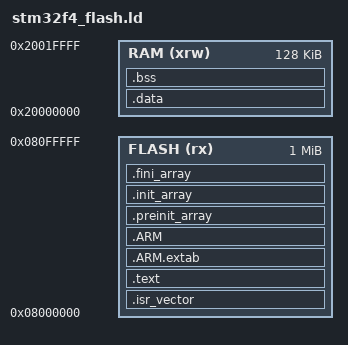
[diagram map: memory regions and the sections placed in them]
ENTRY(Reset_Handler)

/* Stack is placed in the 64KB CCM memory */
/* NB. CCM memory cannot be accessed by peripherals or DMA! */
/* Always use static/global variables with peripherals/DMA. */
_estack = 0x10000000 + 64K;

MEMORY
{
	FLASH (rx)      : ORIGIN = 0x08000000, LENGTH = 1024K
	RAM (xrw)       : ORIGIN = 0x20000000, LENGTH = 128K
}

SECTIONS
{
	/* Reset Vector */
	.isr_vector :
	{
		. = ALIGN(4);
		KEEP(*(.isr_vector))
		. = ALIGN(4);
	} >FLASH

	.text :
	{
		. = ALIGN(4);
		*(.text)
		*(.text*)
		*(.rodata)
		*(.rodata*)
		*(.glue_7)         /* glue arm to thumb code */
		*(.glue_7t)        /* glue thumb to arm code */
		*(.eh_frame)

		KEEP (*(.init))
		KEEP (*(.fini))

		. = ALIGN(4);
		_etext = .;
		_exit = .;
	} >FLASH

	.ARM.extab : { *(.ARM.extab* .gnu.linkonce.armextab.*) } >FLASH
	.ARM : {
		__exidx_start = .;
		*(.ARM.exidx*)
		__exidx_end = .;
	} >FLASH

	.preinit_array :
	{
		PROVIDE_HIDDEN (__preinit_array_start = .);
		KEEP (*(.preinit_array*))
		PROVIDE_HIDDEN (__preinit_array_end = .);
	} >FLASH

	.init_array :
	{
		PROVIDE_HIDDEN (__init_array_start = .);
		KEEP (*(SORT(.init_array.*)))
		KEEP (*(.init_array*))
		PROVIDE_HIDDEN (__init_array_end = .);
	} >FLASH

	.fini_array :
	{
		PROVIDE_HIDDEN (__fini_array_start = .);
		KEEP (*(.fini_array*))
		KEEP (*(SORT(.fini_array.*)))
		PROVIDE_HIDDEN (__fini_array_end = .);
	} >FLASH

	_sidata = .;

	.data : AT ( _sidata )
	{
		. = ALIGN(4);
		_sdata = .;
		*(.data)
		*(.data*)
		. = ALIGN(4);
		_edata = .;
	} >RAM

	. = ALIGN(4);
	.bss :
	{
		_sbss = .;
		__bss_start__ = _sbss;
		*(.bss)
		*(.bss*)
		*(COMMON)
		. = ALIGN(4);
		_ebss = .;
		__bss_end__ = _ebss;
	} >RAM

	/* Remove information from the standard libraries */
	/DISCARD/ :
	{
		libc.a ( * )
		libm.a ( * )
		libgcc.a ( * )
	}

	.ARM.attributes 0 : { *(.ARM.attributes) }
}
